AUTOSAR XML (schema 00046)
package /McInt/SwComponents
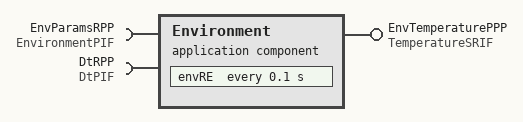
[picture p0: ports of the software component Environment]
  application sw component type Environment
    provide port EnvTemperaturePPP: provided-interface=TemperatureSRIF  # Port to send out the temperature of the environment
    require port EnvParamsRPP: required-interface=EnvironmentPIF  # Port to get the parameters for the environment
    require port DtRPP: required-interface=DtPIF  # Port to get delta t, i.e. time of one time step
    behavior EnvironmentInternalBehavior: data-type-mapping=DataTypeMappingSet, handle-termination-and-restart=NO-SUPPORT
      ar-typed-per-instance-memorys:
        data THighLimit: sw-addr-method=CODE, sw-calibration-access=READ-ONLY, type=Temperature_C  # Measurement point for the upper limit of the generated temperature profile
      timing event env100ms: start-on-event=envRE, period=0.1
      implicit-inter-runnable-variables:
        data Seed: sw-addr-method=CODE, type=uint32, init-value=5323  # Internal state of the environment: the current seed for the (pseudo) random number generation
        data TEnv: sw-addr-method=CODE, sw-calibration-access=READ-ONLY, type=Temperature_C, init-value=20 DegreeCelsius  # Internal state of the environment: the temperture of the environment
      runnable envRE: sw-addr-method=CODE, symbol=envRE_func
        data-write-access:
          access DWA_T: accessed-variable=EnvTemperaturePPP.T
        4 x parameter access:
          PA_Dt: accessed-parameter=DtRPP.Dt
          PA_TLowLimit: accessed-parameter=EnvParamsRPP.env_TLowLimit
          PA_TStepSize: accessed-parameter=EnvParamsRPP.env_TStepSize
          PA_THighLimitDistance: accessed-parameter=EnvParamsRPP.env_THighLimitDistance
        read-local-variables:
          access ReadLocalVariables_Seed: accessed-variable=Seed
          access ReadLocalVariables_TEnv: accessed-variable=TEnv
        written-local-variables:
          access WrittenLocalVariables_Seed: accessed-variable=Seed
          access WrittenLocalVariables_TEnv: accessed-variable=TEnv
